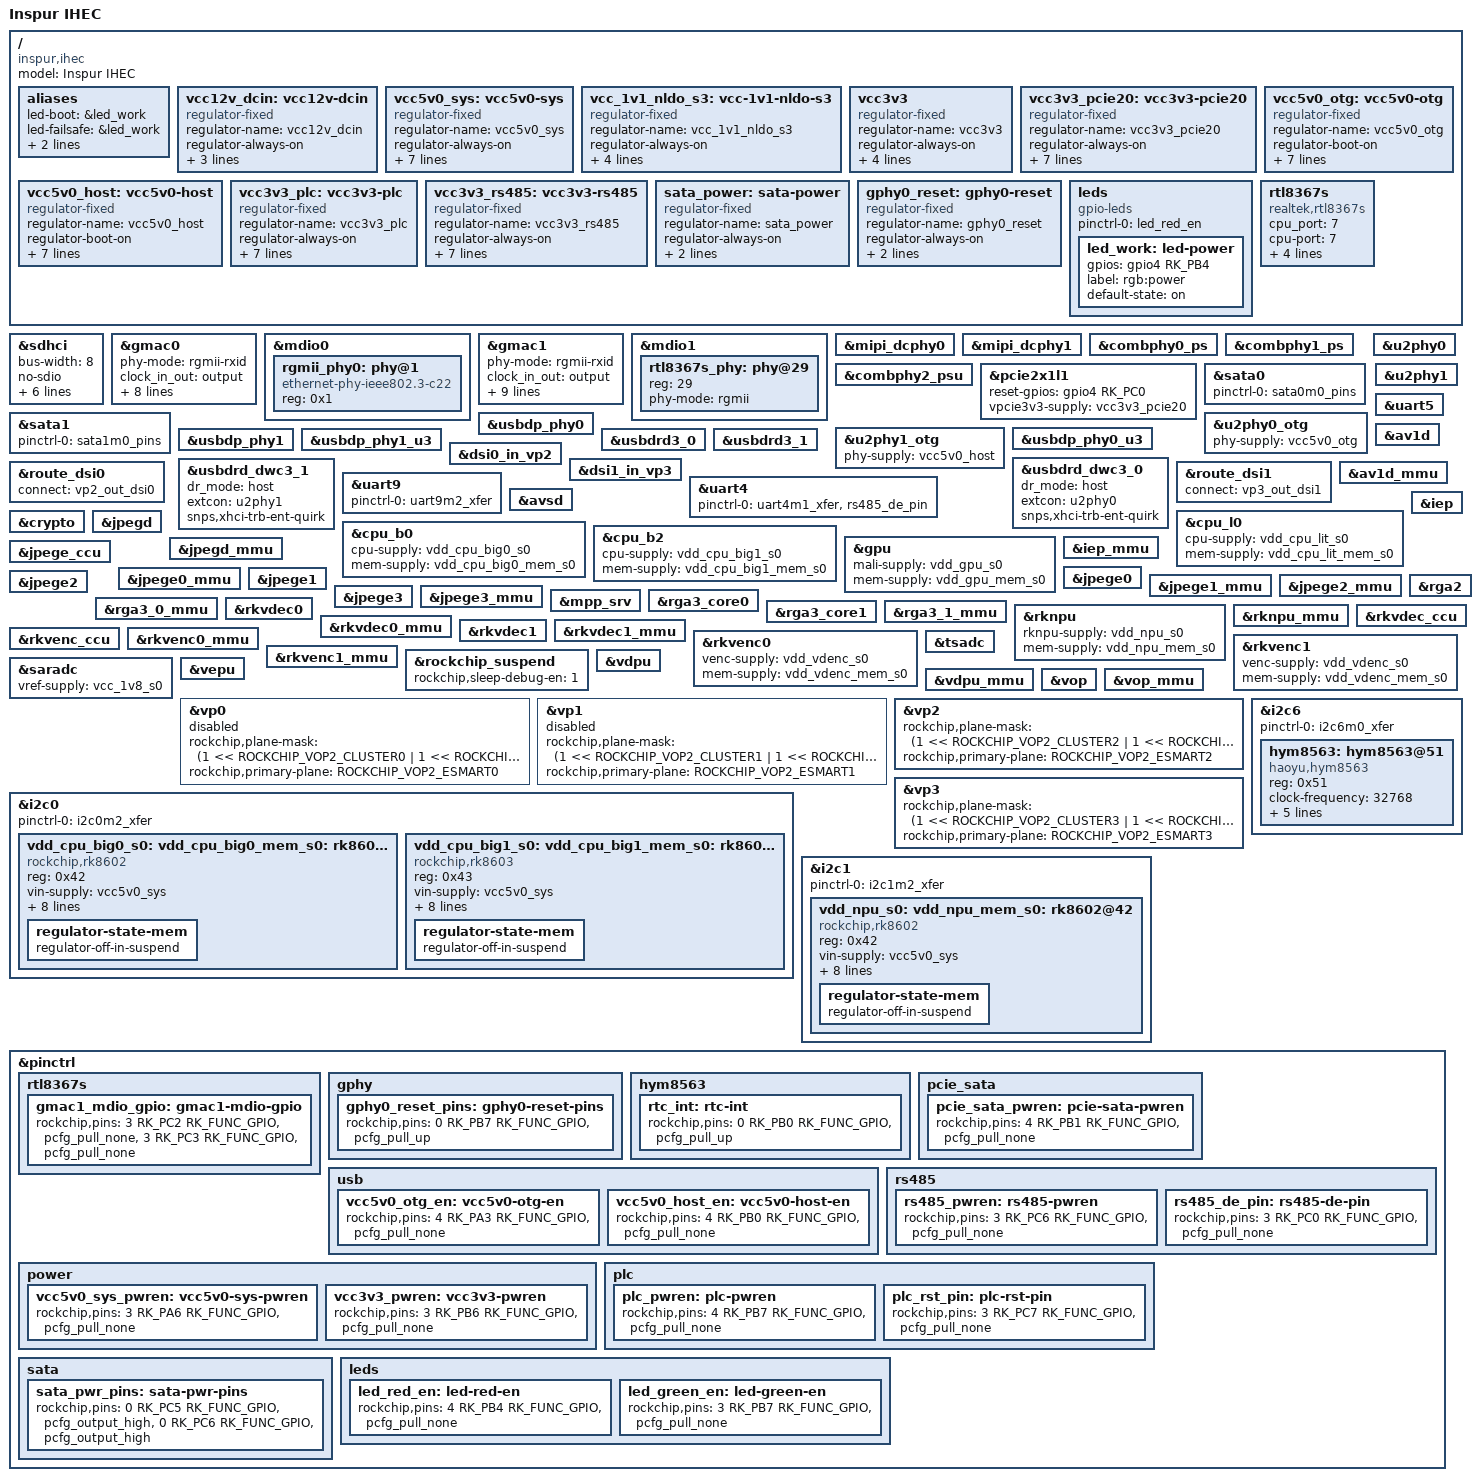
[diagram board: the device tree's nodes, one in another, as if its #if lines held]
// SPDX-License-Identifier: (GPL-2.0+ OR MIT)
/*
* Copyright (c) 2023 Rockchip Electronics Co., Ltd.
*/

#include <dt-bindings/gpio/gpio.h>
#include <dt-bindings/leds/common.h>
#include <dt-bindings/pwm/pwm.h>
#include <dt-bindings/pinctrl/rockchip.h>
#include <dt-bindings/input/rk-input.h>
#include <dt-bindings/display/drm_mipi_dsi.h>
#include <dt-bindings/display/rockchip_vop.h>
#include <dt-bindings/sensor-dev.h>
#include "dt-bindings/usb/pd.h"
#include "rk3588.dtsi"
#include "rk3588-rk806-single.dtsi"
#include "rk3588-linux.dtsi"

/ {
	model = "Inspur IHEC";
	compatible = "inspur,ihec", "rockchip,rk3588";

	aliases {
		led-boot = &led_work;
		led-failsafe = &led_work;
		led-running = &led_work;
		led-upgrade = &led_work;
	};

	vcc12v_dcin: vcc12v-dcin {
		compatible = "regulator-fixed";
		regulator-name = "vcc12v_dcin";
		regulator-always-on;
		regulator-boot-on;
		regulator-min-microvolt = <12000000>;
		regulator-max-microvolt = <12000000>;
	};

	vcc5v0_sys: vcc5v0-sys {
		compatible = "regulator-fixed";
		regulator-name = "vcc5v0_sys";
		regulator-always-on;
		regulator-boot-on;
		regulator-min-microvolt = <5000000>;
		regulator-max-microvolt = <5000000>;
		pinctrl-names = "default";
		pinctrl-0 = <&vcc5v0_sys_pwren>;
		enable-active-high;
		gpio = <&gpio3 RK_PA6 GPIO_ACTIVE_HIGH>;
		vin-supply = <&vcc12v_dcin>;
	};

	vcc_1v1_nldo_s3: vcc-1v1-nldo-s3 {
		compatible = "regulator-fixed";
		regulator-name = "vcc_1v1_nldo_s3";
		regulator-always-on;
		regulator-boot-on;
		regulator-min-microvolt = <1100000>;
		regulator-max-microvolt = <1100000>;
		vin-supply = <&vcc5v0_sys>;
	};

	vcc3v3: vcc3v3 {
		compatible = "regulator-fixed";
		regulator-name = "vcc3v3";
		regulator-always-on;
		regulator-boot-on;
		regulator-min-microvolt = <3300000>;
		regulator-max-microvolt = <3300000>;
#if 0
		pinctrl-names = "default";
		pinctrl-0 = <&vcc3v3_pwren>;
		enable-active-high;
		gpio = <&gpio3 RK_PB6 GPIO_ACTIVE_HIGH>;
		vin-supply = <&vcc12v_dcin>;
#else
		vin-supply = <&vcc_3v3_s3>;
#endif
	};

	vcc3v3_pcie20: vcc3v3-pcie20 {
		compatible = "regulator-fixed";
		regulator-name = "vcc3v3_pcie20";
		regulator-always-on;
		regulator-boot-on;
		regulator-min-microvolt = <3300000>;
		regulator-max-microvolt = <3300000>;
		pinctrl-names = "default";
		pinctrl-0 = <&pcie_sata_pwren>;
		enable-active-high;
		gpio = <&gpio4 RK_PB1 GPIO_ACTIVE_HIGH>;
		vin-supply = <&vcc3v3>;
	};

	vcc5v0_otg: vcc5v0-otg {
		compatible = "regulator-fixed";
		regulator-name = "vcc5v0_otg";
		regulator-boot-on;
		regulator-always-on;
		regulator-min-microvolt = <5000000>;
		regulator-max-microvolt = <5000000>;
		enable-active-high;
		gpio = <&gpio4 RK_PA3 GPIO_ACTIVE_HIGH>;
		vin-supply = <&vcc5v0_sys >;
		pinctrl-names = "default";
		pinctrl-0 = <&vcc5v0_otg_en>;
	};

	vcc5v0_host: vcc5v0-host {
		compatible = "regulator-fixed";
		regulator-name = "vcc5v0_host";
		regulator-boot-on;
		regulator-always-on;
		regulator-min-microvolt = <5000000>;
		regulator-max-microvolt = <5000000>;
		enable-active-high;
		gpio = <&gpio4 RK_PB0 GPIO_ACTIVE_HIGH>;
		vin-supply = <&vcc5v0_sys >;
		pinctrl-names = "default";
		pinctrl-0 = <&vcc5v0_host_en>;
	};

	vcc3v3_plc: vcc3v3-plc {
		compatible = "regulator-fixed";
		regulator-name = "vcc3v3_plc";
		regulator-always-on;
		regulator-boot-on;
		regulator-min-microvolt = <3300000>;
		regulator-max-microvolt = <3300000>;
		pinctrl-names = "default";
		pinctrl-0 = <&plc_pwren &plc_rst_pin>;
		enable-active-high;
		gpio = <&gpio4 RK_PB7 GPIO_ACTIVE_HIGH>;
		vin-supply = <&vcc3v3>;
	};

	vcc3v3_rs485: vcc3v3-rs485 {
		compatible = "regulator-fixed";
		regulator-name = "vcc3v3_rs485";
		regulator-always-on;
		regulator-boot-on;
		regulator-min-microvolt = <3300000>;
		regulator-max-microvolt = <3300000>;
		pinctrl-names = "default";
		pinctrl-0 = <&rs485_pwren>;
		enable-active-high;
		gpio = <&gpio3 RK_PC6 GPIO_ACTIVE_HIGH>;
		vin-supply = <&vcc3v3>;
	};

	sata_power: sata-power {
		compatible = "regulator-fixed";
		regulator-name = "sata_power";
		regulator-always-on;
		regulator-boot-on;
		pinctrl-names = "default";
		pinctrl-0 = <&sata_pwr_pins>;
	};

	gphy0_reset: gphy0-reset {
		compatible = "regulator-fixed";
		regulator-name = "gphy0_reset";
		regulator-always-on;
		regulator-boot-on;
		pinctrl-names = "default";
		pinctrl-0 = <&gphy0_reset_pins>;
	};

	leds {
		compatible = "gpio-leds";
		pinctrl-names = "default";
		pinctrl-0 =
			<&led_red_en>;

		led_work: led-power {
			gpios = <&gpio4 RK_PB4 GPIO_ACTIVE_HIGH>;
			label = "rgb:power";
			default-state = "on";
		};
	};

	rtl8367s {
		compatible = "realtek,rtl8367s", "realtek,rtl8367c", "realtek,rtl8367b";
		cpu_port = <7>;
		cpu-port = <7>;
		realtek,extif2 = <1 0 1 1 1 1 1 1 2>;
#ifndef INSPUR_RTL8367S_MDIO_GPIO
		mii-bus = <&mdio1>;
		phy_id = <29>;
		phy-id = <29>;
#else
		pinctrl-names = "default";
		pinctrl-0 = <&gmac1_mdio_gpio>;
		gpio-sck = <&gpio3 RK_PC2 GPIO_ACTIVE_HIGH>;
		gpio-sda = <&gpio3 RK_PC3 GPIO_ACTIVE_HIGH>;

		mdio-bus {
			#address-cells = <1>;
			#size-cells = <0>;
			status = "okay";

			rtl8367s_phy: ethernet-phy@29 {
				reg = <29>;
				phy-mode = "rgmii";
			};
		};
#endif
	};
};

//=============================================================

&sdhci {
	bus-width = <8>;
	no-sdio;
	no-sd;
	non-removable;
	max-frequency = <200000000>;
	mmc-hs400-1_8v;
	mmc-hs400-enhanced-strobe;
	full-pwr-cycle-in-suspend;
	status = "okay";
};

&gmac0 {
	phy-mode = "rgmii-rxid";
	clock_in_out = "output";

	snps,reset-gpio = <&gpio0 RK_PB7 GPIO_ACTIVE_LOW>;
	snps,reset-active-low;
	/* Reset time is 20ms, 100ms for rtl8211f */
	snps,reset-delays-us = <0 20000 100000>;

	phy-handle = <&rgmii_phy0>;
	pinctrl-names = "default";
	pinctrl-0 = <&gmac0_miim
		     &gmac0_tx_bus2
		     &gmac0_rx_bus2
		     &gmac0_rgmii_clk
		     &gmac0_rgmii_bus>;

	tx_delay = <0x44>;
	status = "okay";
};

&mdio0 {
	rgmii_phy0: phy@1 {
		compatible = "ethernet-phy-ieee802.3-c22";
		reg = <0x1>;
	};
};

&gmac1 {
	/* Use rgmii-rxid mode to disable rx delay inside Soc */
	phy-mode = "rgmii-rxid";
	clock_in_out = "output";

	snps,no-vlhash;
	snps,reset-gpio = <&gpio3 RK_PC1 GPIO_ACTIVE_LOW>;
	snps,reset-active-low;
	/* Reset time is 20ms, 100ms for rtl8211f */
	snps,reset-delays-us = <0 20000 100000>;

	pinctrl-names = "default";
	pinctrl-0 = <
#ifndef INSPUR_RTL8367S_MDIO_GPIO
			&gmac1_miim
#endif
			&gmac1_tx_bus2
			&gmac1_rx_bus2
			&gmac1_rgmii_clk
			&gmac1_rgmii_bus>;

	tx_delay = <0x42>;
	/* rx_delay = <0x4f>; */

	status = "okay";
#ifdef INSPUR_RTL8367S_M2P
	phy-handle = <&rtl8367s_phy>;
#else
	fixed-link {
		speed = <1000>;
		full-duplex;
		pause;
	};
#endif
};

#ifndef INSPUR_RTL8367S_MDIO_GPIO
#ifdef INSPUR_RTL8367S_M2P
&mdio1 {
	rtl8367s_phy: phy@29 {
		reg = <29>;
		phy-mode = "rgmii";
	};
};
#endif
#endif

&mipi_dcphy0 {
	status = "okay";
};

&mipi_dcphy1 {
	status = "okay";
};

// COMBOPHY
/// SATA (&sata0)
&combphy0_ps {
	status = "okay";
};

/// SATA (&sata1)
&combphy1_ps {
	status = "okay";
};

/// PCIE (&pcie2x1l1) => ASM1061 => SATA x 2
&combphy2_psu {
	status = "okay";
};

// PCIE
&pcie2x1l1 {
	reset-gpios = <&gpio4 RK_PC0 GPIO_ACTIVE_HIGH>;
	vpcie3v3-supply = <&vcc3v3_pcie20>;
	status = "okay";
};

// SATA
&sata0 {
	pinctrl-names = "default";
	pinctrl-0 = <&sata0m0_pins>;
	status = "okay";
};

&sata1 {
	pinctrl-names = "default";
	pinctrl-0 = <&sata1m0_pins>;
	status = "okay";
};

// USB
&u2phy0 {
	status = "okay";
};

&u2phy0_otg {
	phy-supply = <&vcc5v0_otg>;
	status = "okay";
};

&u2phy1 {
	status = "okay";
};

&u2phy1_otg {
	phy-supply = <&vcc5v0_host>;
	status = "okay";
};

&usbdp_phy0 {
	status = "okay";
};

&usbdp_phy0_u3 {
	status = "okay";
};

&usbdp_phy1 {
	status = "okay";
};

&usbdp_phy1_u3 {
	status = "okay";
};

&usbdrd3_0 {
	status = "okay";
};

&usbdrd_dwc3_0 {
	dr_mode = "host";
	extcon = <&u2phy0>;
	snps,xhci-trb-ent-quirk;
	status = "okay";
};

&usbdrd3_1 {
	status = "okay";
};

&usbdrd_dwc3_1 {
	dr_mode = "host";
	extcon = <&u2phy1>;
	snps,xhci-trb-ent-quirk;
	status = "okay";
};

// Display
/// MIPI DSI

&dsi0_in_vp2 {
	status = "okay";
};

&dsi1_in_vp3 {
	status = "okay";
};

&route_dsi0 {
	status = "okay";
	connect = <&vp2_out_dsi0>;
};

&route_dsi1 {
	status = "okay";
	connect = <&vp3_out_dsi1>;
};

// UART

&uart4 {
	pinctrl-names = "default";
	pinctrl-0 = <&uart4m1_xfer &rs485_de_pin>;
	status = "okay";
};

&uart5 {
	status = "okay";
};

&uart9 {
	pinctrl-0 = <&uart9m2_xfer>;
	status = "okay";
};

// OnChip

&av1d {
	status = "okay";
};

&av1d_mmu {
	status = "okay";
};

&avsd {
	status = "okay";
};

&cpu_l0 {
	cpu-supply = <&vdd_cpu_lit_s0>;
	mem-supply = <&vdd_cpu_lit_mem_s0>;
};

&cpu_b0 {
	cpu-supply = <&vdd_cpu_big0_s0>;
	mem-supply = <&vdd_cpu_big0_mem_s0>;
};

&cpu_b2 {
	cpu-supply = <&vdd_cpu_big1_s0>;
	mem-supply = <&vdd_cpu_big1_mem_s0>;
};

&crypto {
	status = "okay";
};

&gpu {
	mali-supply = <&vdd_gpu_s0>;
	mem-supply = <&vdd_gpu_mem_s0>;
	status = "okay";
};

&iep {
	status = "okay";
};

&iep_mmu {
	status = "okay";
};

&jpegd {
	status = "okay";
};

&jpegd_mmu {
	status = "okay";
};

&jpege_ccu {
	status = "okay";
};

&jpege0 {
	status = "okay";
};

&jpege0_mmu {
	status = "okay";
};

&jpege1 {
	status = "okay";
};

&jpege1_mmu {
	status = "okay";
};

&jpege2 {
	status = "okay";
};

&jpege2_mmu {
	status = "okay";
};

&jpege3 {
	status = "okay";
};

&jpege3_mmu {
	status = "okay";
};

&mpp_srv {
	status = "okay";
};

&rga3_core0 {
	status = "okay";
};

&rga3_0_mmu {
	status = "okay";
};

&rga3_core1 {
	status = "okay";
};

&rga3_1_mmu {
	status = "okay";
};

&rga2 {
	status = "okay";
};

&rknpu {
	rknpu-supply = <&vdd_npu_s0>;
	mem-supply = <&vdd_npu_mem_s0>;
	status = "okay";
};

&rknpu_mmu {
	status = "okay";
};

&rkvdec_ccu {
	status = "okay";
};

&rkvdec0 {
	status = "okay";
};

&rkvdec0_mmu {
	status = "okay";
};

&rkvdec1 {
	status = "okay";
};

&rkvdec1_mmu {
	status = "okay";
};

&rkvenc_ccu {
	status = "okay";
};

&rkvenc0 {
	venc-supply = <&vdd_vdenc_s0>;
	mem-supply = <&vdd_vdenc_mem_s0>;
	status = "okay";
};

&rkvenc0_mmu {
	status = "okay";
};

&rkvenc1 {
	venc-supply = <&vdd_vdenc_s0>;
	mem-supply = <&vdd_vdenc_mem_s0>;
	status = "okay";
};

&rkvenc1_mmu {
	status = "okay";
};

&rockchip_suspend {
	status = "okay";
	rockchip,sleep-debug-en = <1>;
};

&saradc {
	status = "okay";
	vref-supply = <&vcc_1v8_s0>;
};

&tsadc {
	status = "okay";
};

&vdpu {
	status = "okay";
};

&vdpu_mmu {
	status = "okay";
};

&vepu {
	status = "okay";
};

&vop {
	status = "okay";
};

&vop_mmu {
	status = "okay";
};

/* vp0 & vp1 splice for 8K output */
&vp0 {
	rockchip,plane-mask = <(1 << ROCKCHIP_VOP2_CLUSTER0 | 1 << ROCKCHIP_VOP2_ESMART0)>;
	rockchip,primary-plane = <ROCKCHIP_VOP2_ESMART0>;
	status = "disabled";
};

&vp1 {
	rockchip,plane-mask = <(1 << ROCKCHIP_VOP2_CLUSTER1 | 1 << ROCKCHIP_VOP2_ESMART1)>;
	rockchip,primary-plane = <ROCKCHIP_VOP2_ESMART1>;
	status = "disabled";
};

&vp2 {
	rockchip,plane-mask = <(1 << ROCKCHIP_VOP2_CLUSTER2 | 1 << ROCKCHIP_VOP2_ESMART2)>;
	rockchip,primary-plane = <ROCKCHIP_VOP2_ESMART2>;
};

&vp3 {
	rockchip,plane-mask = <(1 << ROCKCHIP_VOP2_CLUSTER3 | 1 << ROCKCHIP_VOP2_ESMART3)>;
	rockchip,primary-plane = <ROCKCHIP_VOP2_ESMART3>;
};

//=============================================================

&i2c0 {
	status = "okay";
	pinctrl-names = "default";
	pinctrl-0 = <&i2c0m2_xfer>;

	vdd_cpu_big0_s0: vdd_cpu_big0_mem_s0: rk8602@42 {
		compatible = "rockchip,rk8602";
		reg = <0x42>;
		vin-supply = <&vcc5v0_sys>;
		regulator-compatible = "rk860x-reg";
		regulator-name = "vdd_cpu_big0_s0";
		regulator-min-microvolt = <550000>;
		regulator-max-microvolt = <1050000>;
		regulator-ramp-delay = <2300>;
		rockchip,suspend-voltage-selector = <1>;
		regulator-boot-on;
		regulator-always-on;
		regulator-state-mem {
			regulator-off-in-suspend;
		};
	};

	vdd_cpu_big1_s0: vdd_cpu_big1_mem_s0: rk8603@43 {
		compatible = "rockchip,rk8603";
		reg = <0x43>;
		vin-supply = <&vcc5v0_sys>;
		regulator-compatible = "rk860x-reg";
		regulator-name = "vdd_cpu_big1_s0";
		regulator-min-microvolt = <550000>;
		regulator-max-microvolt = <1050000>;
		regulator-ramp-delay = <2300>;
		rockchip,suspend-voltage-selector = <1>;
		regulator-boot-on;
		regulator-always-on;
		regulator-state-mem {
			regulator-off-in-suspend;
		};
	};
};

&i2c1 {
	status = "okay";
	pinctrl-names = "default";
	pinctrl-0 = <&i2c1m2_xfer>;

	vdd_npu_s0: vdd_npu_mem_s0: rk8602@42 {
		compatible = "rockchip,rk8602";
		reg = <0x42>;
		vin-supply = <&vcc5v0_sys>;
		regulator-compatible = "rk860x-reg";
		regulator-name = "vdd_npu_s0";
		regulator-min-microvolt = <550000>;
		regulator-max-microvolt = <950000>;
		regulator-ramp-delay = <2300>;
		rockchip,suspend-voltage-selector = <1>;
		regulator-boot-on;
		regulator-always-on;
		regulator-state-mem {
			regulator-off-in-suspend;
		};
	};
};

&i2c6 {
	status = "okay";
	pinctrl-names = "default";
	pinctrl-0 = <&i2c6m0_xfer>;

	hym8563: hym8563@51 {
		compatible = "haoyu,hym8563";
		reg = <0x51>;
		#clock-cells = <0>;
		clock-frequency = <32768>;
		clock-output-names = "hym8563";
		pinctrl-names = "default";
		pinctrl-0 = <&rtc_int>;

		interrupt-parent = <&gpio0>;
		interrupts = <RK_PB0 IRQ_TYPE_LEVEL_LOW>;
		wakeup-source;
	};
};

&pinctrl {
	rtl8367s {
		/omit-if-no-ref/
		gmac1_mdio_gpio: gmac1-mdio-gpio {
			rockchip,pins =
				/* gmac1_mdc */
				<3 RK_PC2 RK_FUNC_GPIO &pcfg_pull_none>,
				/* gmac1_mdio */
				<3 RK_PC3 RK_FUNC_GPIO &pcfg_pull_none>;
		};
	};
	gphy {
		gphy0_reset_pins: gphy0-reset-pins {
			rockchip,pins =
				<0 RK_PB7 RK_FUNC_GPIO &pcfg_pull_up>;
		};
	};
	hym8563 {
		rtc_int: rtc-int {
			rockchip,pins = <0 RK_PB0 RK_FUNC_GPIO &pcfg_pull_up>;
		};
	};
	usb {
		vcc5v0_otg_en: vcc5v0-otg-en {
			rockchip,pins = <4 RK_PA3 RK_FUNC_GPIO &pcfg_pull_none>;
		};
		vcc5v0_host_en: vcc5v0-host-en {
			rockchip,pins = <4 RK_PB0 RK_FUNC_GPIO &pcfg_pull_none>;
		};
	};
	pcie_sata {
		pcie_sata_pwren: pcie-sata-pwren {
			rockchip,pins = <4 RK_PB1 RK_FUNC_GPIO &pcfg_pull_none>;
		};
	};
	power {
		vcc5v0_sys_pwren: vcc5v0-sys-pwren {
			rockchip,pins = <3 RK_PA6 RK_FUNC_GPIO &pcfg_pull_none>;
		};
		/omit-if-no-ref/
		vcc3v3_pwren: vcc3v3-pwren {
			rockchip,pins = <3 RK_PB6 RK_FUNC_GPIO &pcfg_pull_none>;
		};
	};
	rs485 {
		rs485_pwren: rs485-pwren {
			rockchip,pins = <3 RK_PC6 RK_FUNC_GPIO &pcfg_pull_none>;
		};
		rs485_de_pin: rs485-de-pin {
			rockchip,pins = <3 RK_PC0 RK_FUNC_GPIO &pcfg_pull_none>;
		};
	};
	plc {
		plc_pwren: plc-pwren {
			rockchip,pins = <4 RK_PB7 RK_FUNC_GPIO &pcfg_pull_none>;
		};
		plc_rst_pin: plc-rst-pin {
			rockchip,pins = <3 RK_PC7 RK_FUNC_GPIO &pcfg_pull_none>;
		};
	};
	sata {
		/omit-if-no-ref/
		sata_pwr_pins: sata-pwr-pins {
			rockchip,pins =
				/* hdd1 pwr */
				<0 RK_PC5 RK_FUNC_GPIO &pcfg_output_high>,
				/* hdd2 pwr */
				<0 RK_PC6 RK_FUNC_GPIO &pcfg_output_high>;
				/* hdd3 pwr */
				// <0 RK_PB7 RK_FUNC_GPIO &pcfg_output_high>,
				/* hdd4 pwr */
				// <0 RK_PD3 RK_FUNC_GPIO &pcfg_output_high>;
		};
	};

	leds {
		led_red_en: led-red-en {
			rockchip,pins =
				<4 RK_PB4 RK_FUNC_GPIO &pcfg_pull_none>;
		};
		led_green_en: led-green-en {
			rockchip,pins =
				<3 RK_PB7 RK_FUNC_GPIO &pcfg_pull_none>;
		};
	};
};
